# max32665 register map
Vendor: Maxim-Integrated; Series: ARMCM3; File version: 1.0
CPU: CM4 r2p1, little endian, MPU, FPU, 3 interrupt priority bits
Registers are 32-bit, read-write, reset 0x0 unless marked. A register's access mark holds for its fields unless they carry their own. Offsets are from the block's base; [hi:lo] are bit positions; {n}, {i} and the like mark numbered series.

## RPU — Resource Protection Unit
Base 0x40002000
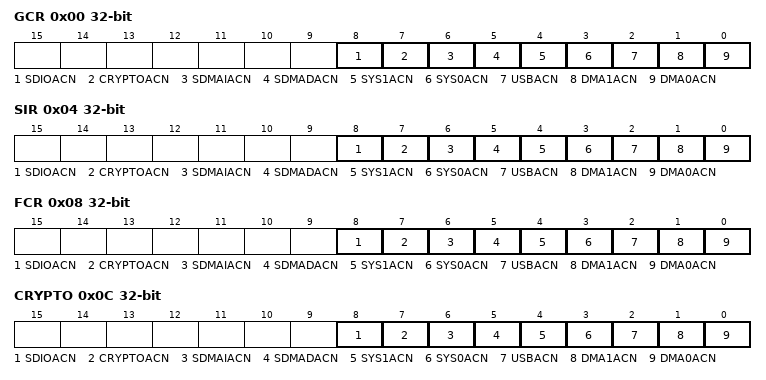
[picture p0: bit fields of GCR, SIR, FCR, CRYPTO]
0x00 GCR (reset mask 0xFFFFFE00) — GCR Protection Register
  [all] fields
    1=dis (Disallow); 0=allow
  [8] SDIOACN — Allow/Disallow SDIO access to the GCR
  [7] CRYPTOACN — Allow/Disallow CRYPTO access to the GCR
  [6] SDMAIACN — Allow/Disallow SDMA Instruction access to the GCR
  [5] SDMADACN — Allow/Disallow SDMA Data access to the GCR
  [4] SYS1ACN — Allow/Disallow SYS1 access to the GCR
  [3] SYS0ACN — Allow/Disallow SYS0 access to the GCR
  [2] USBACN — Allow/Disallow USB access to the GCR
  [1] DMA1ACN — Allow/Disallow DMA1 access to the GCR
  [0] DMA0ACN — Allow/Disallow DMA0 access to the GCR
0x04 SIR (reset mask 0xFFFFFE00) — SIR Protection Register
  [all] fields
    1=dis (Disallow); 0=allow
  [8] SDIOACN — Allow/Disallow SDIO access to the SIR
  [7] CRYPTOACN — Allow/Disallow CRYPTO access to the SIR
  [6] SDMAIACN — Allow/Disallow SDMA Instruction access to the SIR
  [5] SDMADACN — Allow/Disallow SDMA Data access to the SIR
  [4] SYS1ACN — Allow/Disallow SYS1 access to the SIR
  [3] SYS0ACN — Allow/Disallow SYS0 access to the SIR
  [2] USBACN — Allow/Disallow USB access to the SIR
  [1] DMA1ACN — Allow/Disallow DMA1 access to the SIR
  [0] DMA0ACN — Allow/Disallow DMA0 access to the SIR
0x08 FCR (reset mask 0xFFFFFE00) — FCR Protection Register
  [all] fields
    1=dis (Disallow); 0=allow
  [8] SDIOACN — Allow/Disallow SDIO access to the FCR
  [7] CRYPTOACN — Allow/Disallow CRYPTO access to the FCR
  [6] SDMAIACN — Allow/Disallow SDMA Instruction access to the FCR
  [5] SDMADACN — Allow/Disallow SDMA Data access to the FCR
  [4] SYS1ACN — Allow/Disallow SYS1 access to the FCR
  [3] SYS0ACN — Allow/Disallow SYS0 access to the FCR
  [2] USBACN — Allow/Disallow USB access to the FCR
  [1] DMA1ACN — Allow/Disallow DMA1 access to the FCR
  [0] DMA0ACN — Allow/Disallow DMA0 access to the FCR
0x0C CRYPTO (reset mask 0xFFFFFE00) — Crypto Protection Register
  [all] fields
    1=dis (Disallow); 0=allow
  [8] SDIOACN — Allow/Disallow SDIO access to the Crypto
  [7] CRYPTOACN — Allow/Disallow CRYPTO access to the Crypto
  [6] SDMAIACN — Allow/Disallow SDMA Instruction access to the Crypto
  [5] SDMADACN — Allow/Disallow SDMA Data access to the Crypto
  [4] SYS1ACN — Allow/Disallow SYS1 access to the Crypto
  [3] SYS0ACN — Allow/Disallow SYS0 access to the Crypto
  [2] USBACN — Allow/Disallow USB access to the Crypto
  [1] DMA1ACN — Allow/Disallow DMA1 access to the Crypto
  [0] DMA0ACN — Allow/Disallow DMA0 access to the Crypto
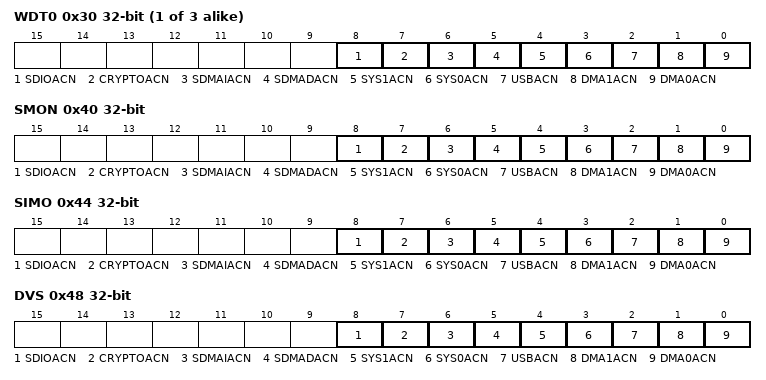
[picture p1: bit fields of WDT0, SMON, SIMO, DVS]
{0x30+4i} WDT{i} (reset mask 0xFFFFFE00) (i=0..2) — Watchdog {i} Protection Register
  [all] fields
    1=dis (Disallow); 0=allow
  [8] SDIOACN — Allow/Disallow SDIO access to the Watchdog {i}
  [7] CRYPTOACN — Allow/Disallow CRYPTO access to the Watchdog {i}
  [6] SDMAIACN — Allow/Disallow SDMA Instruction access to the Watchdog {i}
  [5] SDMADACN — Allow/Disallow SDMA Data access to the Watchdog {i}
  [4] SYS1ACN — Allow/Disallow SYS1 access to the Watchdog {i}
  [3] SYS0ACN — Allow/Disallow SYS0 access to the Watchdog {i}
  [2] USBACN — Allow/Disallow USB access to the Watchdog {i}
  [1] DMA1ACN — Allow/Disallow DMA1 access to the Watchdog {i}
  [0] DMA0ACN — Allow/Disallow DMA0 access to the Watchdog {i}
0x40 SMON (reset mask 0xFFFFFE00) — SMON Protection Register
  [all] fields
    1=dis (Disallow); 0=allow
  [8] SDIOACN — Allow/Disallow SDIO access to the SMON
  [7] CRYPTOACN — Allow/Disallow CRYPTO access to the SMON
  [6] SDMAIACN — Allow/Disallow SDMA Instruction access to the SMON
  [5] SDMADACN — Allow/Disallow SDMA Data access to the SMON
  [4] SYS1ACN — Allow/Disallow SYS1 access to the SMON
  [3] SYS0ACN — Allow/Disallow SYS0 access to the SMON
  [2] USBACN — Allow/Disallow USB access to the SMON
  [1] DMA1ACN — Allow/Disallow DMA1 access to the SMON
  [0] DMA0ACN — Allow/Disallow DMA0 access to the SMON
0x44 SIMO (reset mask 0xFFFFFE00) — SIMO Protection Register
  [all] fields
    1=dis (Disallow); 0=allow
  [8] SDIOACN — Allow/Disallow SDIO access to the SIMO
  [7] CRYPTOACN — Allow/Disallow CRYPTO access to the SIMO
  [6] SDMAIACN — Allow/Disallow SDMA Instruction access to the SIMO
  [5] SDMADACN — Allow/Disallow SDMA Data access to the SIMO
  [4] SYS1ACN — Allow/Disallow SYS1 access to the SIMO
  [3] SYS0ACN — Allow/Disallow SYS0 access to the SIMO
  [2] USBACN — Allow/Disallow USB access to the SIMO
  [1] DMA1ACN — Allow/Disallow DMA1 access to the SIMO
  [0] DMA0ACN — Allow/Disallow DMA0 access to the SIMO
0x48 DVS (reset mask 0xFFFFFE00) — DVS Protection Register
  [all] fields
    1=dis (Disallow); 0=allow
  [8] SDIOACN — Allow/Disallow SDIO access to the DVS
  [7] CRYPTOACN — Allow/Disallow CRYPTO access to the DVS
  [6] SDMAIACN — Allow/Disallow SDMA Instruction access to the DVS
  [5] SDMADACN — Allow/Disallow SDMA Data access to the DVS
  [4] SYS1ACN — Allow/Disallow SYS1 access to the DVS
  [3] SYS0ACN — Allow/Disallow SYS0 access to the DVS
  [2] USBACN — Allow/Disallow USB access to the DVS
  [1] DMA1ACN — Allow/Disallow DMA1 access to the DVS
  [0] DMA0ACN — Allow/Disallow DMA0 access to the DVS
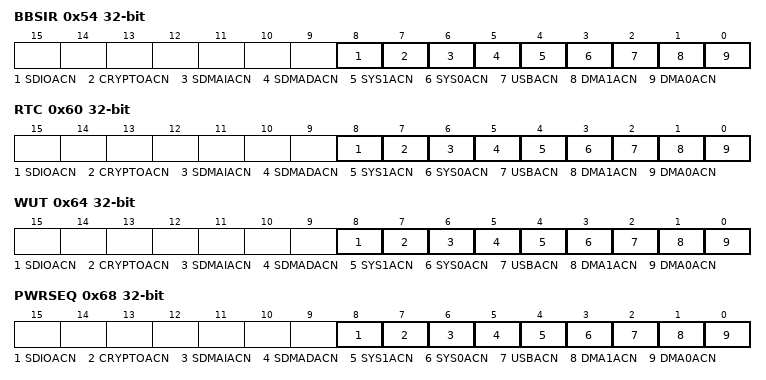
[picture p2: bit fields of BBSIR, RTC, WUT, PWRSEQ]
0x54 BBSIR (reset mask 0xFFFFFE00) — BBSIR Protection Register
  [all] fields
    1=dis (Disallow); 0=allow
  [8] SDIOACN — Allow/Disallow SDIO access to the BBSIR
  [7] CRYPTOACN — Allow/Disallow CRYPTO access to the BBSIR
  [6] SDMAIACN — Allow/Disallow SDMA Instruction access to the BBSIR
  [5] SDMADACN — Allow/Disallow SDMA Data access to the BBSIR
  [4] SYS1ACN — Allow/Disallow SYS1 access to the BBSIR
  [3] SYS0ACN — Allow/Disallow SYS0 access to the BBSIR
  [2] USBACN — Allow/Disallow USB access to the BBSIR
  [1] DMA1ACN — Allow/Disallow DMA1 access to the BBSIR
  [0] DMA0ACN — Allow/Disallow DMA0 access to the BBSIR
0x60 RTC (reset mask 0xFFFFFE00) — RTC Protection Register
  [all] fields
    1=dis (Disallow); 0=allow
  [8] SDIOACN — Allow/Disallow SDIO access to the RTC
  [7] CRYPTOACN — Allow/Disallow CRYPTO access to the RTC
  [6] SDMAIACN — Allow/Disallow SDMA Instruction access to the RTC
  [5] SDMADACN — Allow/Disallow SDMA Data access to the RTC
  [4] SYS1ACN — Allow/Disallow SYS1 access to the RTC
  [3] SYS0ACN — Allow/Disallow SYS0 access to the RTC
  [2] USBACN — Allow/Disallow USB access to the RTC
  [1] DMA1ACN — Allow/Disallow DMA1 access to the RTC
  [0] DMA0ACN — Allow/Disallow DMA0 access to the RTC
0x64 WUT (reset mask 0xFFFFFE00) — Wakeup Timer Protection Register
  [all] fields
    1=dis (Disallow); 0=allow
  [8] SDIOACN — Allow/Disallow SDIO access to the Wakeup Timer
  [7] CRYPTOACN — Allow/Disallow CRYPTO access to the Wakeup Timer
  [6] SDMAIACN — Allow/Disallow SDMA Instruction access to the Wakeup Timer
  [5] SDMADACN — Allow/Disallow SDMA Data access to the Wakeup Timer
  [4] SYS1ACN — Allow/Disallow SYS1 access to the Wakeup Timer
  [3] SYS0ACN — Allow/Disallow SYS0 access to the Wakeup Timer
  [2] USBACN — Allow/Disallow USB access to the Wakeup Timer
  [1] DMA1ACN — Allow/Disallow DMA1 access to the Wakeup Timer
  [0] DMA0ACN — Allow/Disallow DMA0 access to the Wakeup Timer
0x68 PWRSEQ (reset mask 0xFFFFFE00) — Power Sequencer Protection Register
  [all] fields
    1=dis (Disallow); 0=allow
  [8] SDIOACN — Allow/Disallow SDIO access to the Power Sequencer
  [7] CRYPTOACN — Allow/Disallow CRYPTO access to the Power Sequencer
  [6] SDMAIACN — Allow/Disallow SDMA Instruction access to the Power Sequencer
  [5] SDMADACN — Allow/Disallow SDMA Data access to the Power Sequencer
  [4] SYS1ACN — Allow/Disallow SYS1 access to the Power Sequencer
  [3] SYS0ACN — Allow/Disallow SYS0 access to the Power Sequencer
  [2] USBACN — Allow/Disallow USB access to the Power Sequencer
  [1] DMA1ACN — Allow/Disallow DMA1 access to the Power Sequencer
  [0] DMA0ACN — Allow/Disallow DMA0 access to the Power Sequencer
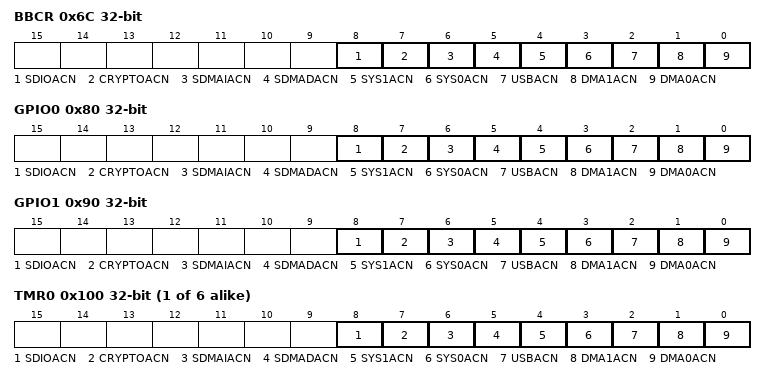
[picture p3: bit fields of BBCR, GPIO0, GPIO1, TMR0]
0x6C BBCR (reset mask 0xFFFFFE00) — BBCR Protection Register
  [all] fields
    1=dis (Disallow); 0=allow
  [8] SDIOACN — Allow/Disallow SDIO access to the BBCR
  [7] CRYPTOACN — Allow/Disallow CRYPTO access to the BBCR
  [6] SDMAIACN — Allow/Disallow SDMA Instruction access to the BBCR
  [5] SDMADACN — Allow/Disallow SDMA Data access to the BBCR
  [4] SYS1ACN — Allow/Disallow SYS1 access to the BBCR
  [3] SYS0ACN — Allow/Disallow SYS0 access to the BBCR
  [2] USBACN — Allow/Disallow USB access to the BBCR
  [1] DMA1ACN — Allow/Disallow DMA1 access to the BBCR
  [0] DMA0ACN — Allow/Disallow DMA0 access to the BBCR
0x80 GPIO0 (reset mask 0xFFFFFE00) — GPIO0 Protection Register
  [all] fields
    1=dis (Disallow); 0=allow
  [8] SDIOACN — Allow/Disallow SDIO access to the GPIO0
  [7] CRYPTOACN — Allow/Disallow CRYPTO access to the GPIO0
  [6] SDMAIACN — Allow/Disallow SDMA Instruction access to the GPIO0
  [5] SDMADACN — Allow/Disallow SDMA Data access to the GPIO0
  [4] SYS1ACN — Allow/Disallow SYS1 access to the GPIO0
  [3] SYS0ACN — Allow/Disallow SYS0 access to the GPIO0
  [2] USBACN — Allow/Disallow USB access to the GPIO0
  [1] DMA1ACN — Allow/Disallow DMA1 access to the GPIO0
  [0] DMA0ACN — Allow/Disallow DMA0 access to the GPIO0
0x90 GPIO1 (reset mask 0xFFFFFE00) — GPIO1 Protection Register
  [all] fields
    1=dis (Disallow); 0=allow
  [8] SDIOACN — Allow/Disallow SDIO access to the GPIO1
  [7] CRYPTOACN — Allow/Disallow CRYPTO access to the GPIO1
  [6] SDMAIACN — Allow/Disallow SDMA Instruction access to the GPIO1
  [5] SDMADACN — Allow/Disallow SDMA Data access to the GPIO1
  [4] SYS1ACN — Allow/Disallow SYS1 access to the GPIO1
  [3] SYS0ACN — Allow/Disallow SYS0 access to the GPIO1
  [2] USBACN — Allow/Disallow USB access to the GPIO1
  [1] DMA1ACN — Allow/Disallow DMA1 access to the GPIO1
  [0] DMA0ACN — Allow/Disallow DMA0 access to the GPIO1
{0x100+0x10*i} TMR{i} (reset mask 0xFFFFFE00) (i=0..5) — TMR{i} Protection Register
  [all] fields
    1=dis (Disallow); 0=allow
  [8] SDIOACN — Allow/Disallow SDIO access to the TMR{i}
  [7] CRYPTOACN — Allow/Disallow CRYPTO access to the TMR{i}
  [6] SDMAIACN — Allow/Disallow SDMA Instruction access to the TMR{i}
  [5] SDMADACN — Allow/Disallow SDMA Data access to the TMR{i}
  [4] SYS1ACN — Allow/Disallow SYS1 access to the TMR{i}
  [3] SYS0ACN — Allow/Disallow SYS0 access to the TMR{i}
  [2] USBACN — Allow/Disallow USB access to the TMR{i}
  [1] DMA1ACN — Allow/Disallow DMA1 access to the TMR{i}
  [0] DMA0ACN — Allow/Disallow DMA0 access to the TMR{i}
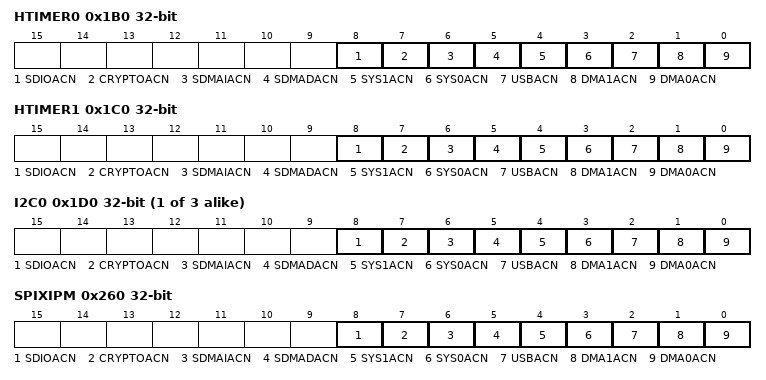
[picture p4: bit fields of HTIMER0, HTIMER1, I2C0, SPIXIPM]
0x1B0 HTIMER0 (reset mask 0xFFFFFE00) — HTimer0 Protection Register
  [all] fields
    1=dis (Disallow); 0=allow
  [8] SDIOACN — Allow/Disallow SDIO access to the HTimer0
  [7] CRYPTOACN — Allow/Disallow CRYPTO access to the HTimer0
  [6] SDMAIACN — Allow/Disallow SDMA Instruction access to the HTimer0
  [5] SDMADACN — Allow/Disallow SDMA Data access to the HTimer0
  [4] SYS1ACN — Allow/Disallow SYS1 access to the HTimer0
  [3] SYS0ACN — Allow/Disallow SYS0 access to the HTimer0
  [2] USBACN — Allow/Disallow USB access to the HTimer0
  [1] DMA1ACN — Allow/Disallow DMA1 access to the HTimer0
  [0] DMA0ACN — Allow/Disallow DMA0 access to the HTimer0
0x1C0 HTIMER1 (reset mask 0xFFFFFE00) — HTimer1 Protection Register
  [all] fields
    1=dis (Disallow); 0=allow
  [8] SDIOACN — Allow/Disallow SDIO access to the HTimer1
  [7] CRYPTOACN — Allow/Disallow CRYPTO access to the HTimer1
  [6] SDMAIACN — Allow/Disallow SDMA Instruction access to the HTimer1
  [5] SDMADACN — Allow/Disallow SDMA Data access to the HTimer1
  [4] SYS1ACN — Allow/Disallow SYS1 access to the HTimer1
  [3] SYS0ACN — Allow/Disallow SYS0 access to the HTimer1
  [2] USBACN — Allow/Disallow USB access to the HTimer1
  [1] DMA1ACN — Allow/Disallow DMA1 access to the HTimer1
  [0] DMA0ACN — Allow/Disallow DMA0 access to the HTimer1
{0x1D0+0x10*i} I2C{i} (reset mask 0xFFFFFE00) (i=0..2) — I2C{i} Protection Register
  [all] fields
    1=dis (Disallow); 0=allow
  [8] SDIOACN — Allow/Disallow SDIO access to the I2C{i}
  [7] CRYPTOACN — Allow/Disallow CRYPTO access to the I2C{i}
  [6] SDMAIACN — Allow/Disallow SDMA Instruction access to the I2C{i}
  [5] SDMADACN — Allow/Disallow SDMA Data access to the I2C{i}
  [4] SYS1ACN — Allow/Disallow SYS1 access to the I2C{i}
  [3] SYS0ACN — Allow/Disallow SYS0 access to the I2C{i}
  [2] USBACN — Allow/Disallow USB access to the I2C{i}
  [1] DMA1ACN — Allow/Disallow DMA1 access to the I2C{i}
  [0] DMA0ACN — Allow/Disallow DMA0 access to the I2C{i}
0x260 SPIXIPM (reset mask 0xFFFFFE00) — SPI-XIP Master Protection Register
  [all] fields
    1=dis (Disallow); 0=allow
  [8] SDIOACN — Allow/Disallow SDIO access to the SPI-XIP Master
  [7] CRYPTOACN — Allow/Disallow CRYPTO access to the SPI-XIP Master
  [6] SDMAIACN — Allow/Disallow SDMA Instruction access to the SPI-XIP Master
  [5] SDMADACN — Allow/Disallow SDMA Data access to the SPI-XIP Master
  [4] SYS1ACN — Allow/Disallow SYS1 access to the SPI-XIP Master
  [3] SYS0ACN — Allow/Disallow SYS0 access to the SPI-XIP Master
  [2] USBACN — Allow/Disallow USB access to the SPI-XIP Master
  [1] DMA1ACN — Allow/Disallow DMA1 access to the SPI-XIP Master
  [0] DMA0ACN — Allow/Disallow DMA0 access to the SPI-XIP Master
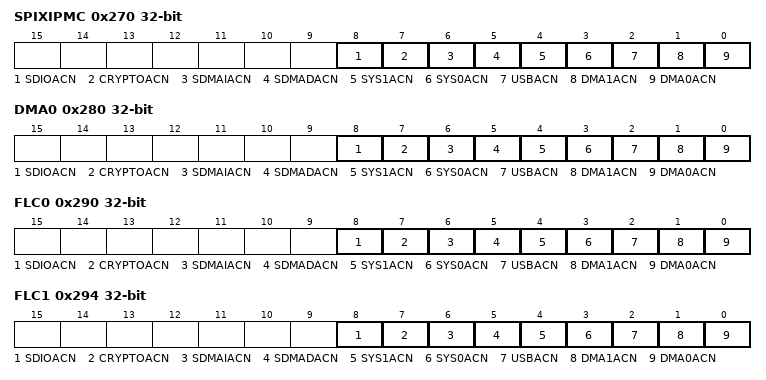
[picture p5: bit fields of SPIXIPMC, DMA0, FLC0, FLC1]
0x270 SPIXIPMC (reset mask 0xFFFFFE00) — SPI-XIP Master Controller Protection Register
  [all] fields
    1=dis (Disallow); 0=allow
  [8] SDIOACN — Allow/Disallow SDIO access to the SPI-XIP Master Controller
  [7] CRYPTOACN — Allow/Disallow CRYPTO access to the SPI-XIP Master Controller
  [6] SDMAIACN — Allow/Disallow SDMA Instruction access to the SPI-XIP Master Controller
  [5] SDMADACN — Allow/Disallow SDMA Data access to the SPI-XIP Master Controller
  [4] SYS1ACN — Allow/Disallow SYS1 access to the SPI-XIP Master Controller
  [3] SYS0ACN — Allow/Disallow SYS0 access to the SPI-XIP Master Controller
  [2] USBACN — Allow/Disallow USB access to the SPI-XIP Master Controller
  [1] DMA1ACN — Allow/Disallow DMA1 access to the SPI-XIP Master Controller
  [0] DMA0ACN — Allow/Disallow DMA0 access to the SPI-XIP Master Controller
0x280 DMA0 (reset mask 0xFFFFFE00) — DMA0 Protection Register
  [all] fields
    1=dis (Disallow); 0=allow
  [8] SDIOACN — Allow/Disallow SDIO access to the DMA0
  [7] CRYPTOACN — Allow/Disallow CRYPTO access to the DMA0
  [6] SDMAIACN — Allow/Disallow SDMA Instruction access to the DMA0
  [5] SDMADACN — Allow/Disallow SDMA Data access to the DMA0
  [4] SYS1ACN — Allow/Disallow SYS1 access to the DMA0
  [3] SYS0ACN — Allow/Disallow SYS0 access to the DMA0
  [2] USBACN — Allow/Disallow USB access to the DMA0
  [1] DMA1ACN — Allow/Disallow DMA1 access to the DMA0
  [0] DMA0ACN — Allow/Disallow DMA0 access to the DMA0
0x290 FLC0 (reset mask 0xFFFFFE00) — Flash 0 Protection Register
  [all] fields
    1=dis (Disallow); 0=allow
  [8] SDIOACN — Allow/Disallow SDIO access to the Flash 0
  [7] CRYPTOACN — Allow/Disallow CRYPTO access to the Flash 0
  [6] SDMAIACN — Allow/Disallow SDMA Instruction access to the Flash 0
  [5] SDMADACN — Allow/Disallow SDMA Data access to the Flash 0
  [4] SYS1ACN — Allow/Disallow SYS1 access to the Flash 0
  [3] SYS0ACN — Allow/Disallow SYS0 access to the Flash 0
  [2] USBACN — Allow/Disallow USB access to the Flash 0
  [1] DMA1ACN — Allow/Disallow DMA1 access to the Flash 0
  [0] DMA0ACN — Allow/Disallow DMA0 access to the Flash 0
0x294 FLC1 (reset mask 0xFFFFFE00) — Flash 1 Protection Register
  [all] fields
    1=dis (Disallow); 0=allow
  [8] SDIOACN — Allow/Disallow SDIO access to the Flash 1
  [7] CRYPTOACN — Allow/Disallow CRYPTO access to the Flash 1
  [6] SDMAIACN — Allow/Disallow SDMA Instruction access to the Flash 1
  [5] SDMADACN — Allow/Disallow SDMA Data access to the Flash 1
  [4] SYS1ACN — Allow/Disallow SYS1 access to the Flash 1
  [3] SYS0ACN — Allow/Disallow SYS0 access to the Flash 1
  [2] USBACN — Allow/Disallow USB access to the Flash 1
  [1] DMA1ACN — Allow/Disallow DMA1 access to the Flash 1
  [0] DMA0ACN — Allow/Disallow DMA0 access to the Flash 1
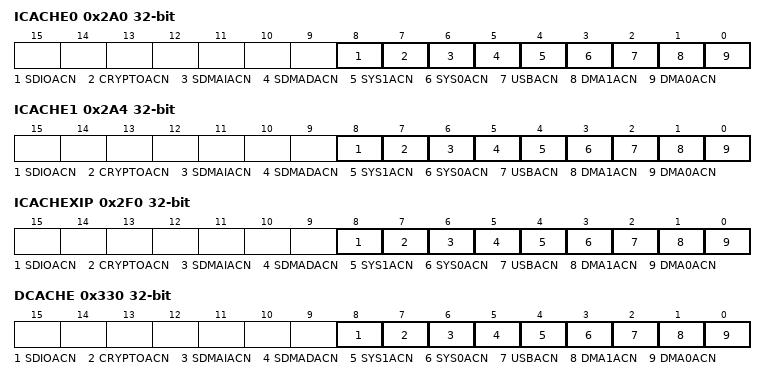
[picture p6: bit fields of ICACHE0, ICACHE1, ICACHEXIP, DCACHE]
0x2A0 ICACHE0 (reset mask 0xFFFFFE00) — Instruction Cache 0 Protection Register
  [all] fields
    1=dis (Disallow); 0=allow
  [8] SDIOACN — Allow/Disallow SDIO access to the Instruction Cache 0
  [7] CRYPTOACN — Allow/Disallow CRYPTO access to the Instruction Cache 0
  [6] SDMAIACN — Allow/Disallow SDMA Instruction access to the Instruction Cache 0
  [5] SDMADACN — Allow/Disallow SDMA Data access to the Instruction Cache 0
  [4] SYS1ACN — Allow/Disallow SYS1 access to the Instruction Cache 0
  [3] SYS0ACN — Allow/Disallow SYS0 access to the Instruction Cache 0
  [2] USBACN — Allow/Disallow USB access to the Instruction Cache 0
  [1] DMA1ACN — Allow/Disallow DMA1 access to the Instruction Cache 0
  [0] DMA0ACN — Allow/Disallow DMA0 access to the Instruction Cache 0
0x2A4 ICACHE1 (reset mask 0xFFFFFE00) — Instruction Cache 1 Protection Register
  [all] fields
    1=dis (Disallow); 0=allow
  [8] SDIOACN — Allow/Disallow SDIO access to the Instruction Cache 1
  [7] CRYPTOACN — Allow/Disallow CRYPTO access to the Instruction Cache 1
  [6] SDMAIACN — Allow/Disallow SDMA Instruction access to the Instruction Cache 1
  [5] SDMADACN — Allow/Disallow SDMA Data access to the Instruction Cache 1
  [4] SYS1ACN — Allow/Disallow SYS1 access to the Instruction Cache 1
  [3] SYS0ACN — Allow/Disallow SYS0 access to the Instruction Cache 1
  [2] USBACN — Allow/Disallow USB access to the Instruction Cache 1
  [1] DMA1ACN — Allow/Disallow DMA1 access to the Instruction Cache 1
  [0] DMA0ACN — Allow/Disallow DMA0 access to the Instruction Cache 1
0x2F0 ICACHEXIP (reset mask 0xFFFFFE00) — Instruction Cache XIP Protection Register
  [all] fields
    1=dis (Disallow); 0=allow
  [8] SDIOACN — Allow/Disallow SDIO access to the Instruction Cache XIP
  [7] CRYPTOACN — Allow/Disallow CRYPTO access to the Instruction Cache XIP
  [6] SDMAIACN — Allow/Disallow SDMA Instruction access to the Instruction Cache XIP
  [5] SDMADACN — Allow/Disallow SDMA Data access to the Instruction Cache XIP
  [4] SYS1ACN — Allow/Disallow SYS1 access to the Instruction Cache XIP
  [3] SYS0ACN — Allow/Disallow SYS0 access to the Instruction Cache XIP
  [2] USBACN — Allow/Disallow USB access to the Instruction Cache XIP
  [1] DMA1ACN — Allow/Disallow DMA1 access to the Instruction Cache XIP
  [0] DMA0ACN — Allow/Disallow DMA0 access to the Instruction Cache XIP
0x330 DCACHE (reset mask 0xFFFFFE00) — Data Cache Controller Protection Register
  [all] fields
    1=dis (Disallow); 0=allow
  [8] SDIOACN — Allow/Disallow SDIO access to the Data Cache Controller
  [7] CRYPTOACN — Allow/Disallow CRYPTO access to the Data Cache Controller
  [6] SDMAIACN — Allow/Disallow SDMA Instruction access to the Data Cache Controller
  [5] SDMADACN — Allow/Disallow SDMA Data access to the Data Cache Controller
  [4] SYS1ACN — Allow/Disallow SYS1 access to the Data Cache Controller
  [3] SYS0ACN — Allow/Disallow SYS0 access to the Data Cache Controller
  [2] USBACN — Allow/Disallow USB access to the Data Cache Controller
  [1] DMA1ACN — Allow/Disallow DMA1 access to the Data Cache Controller
  [0] DMA0ACN — Allow/Disallow DMA0 access to the Data Cache Controller
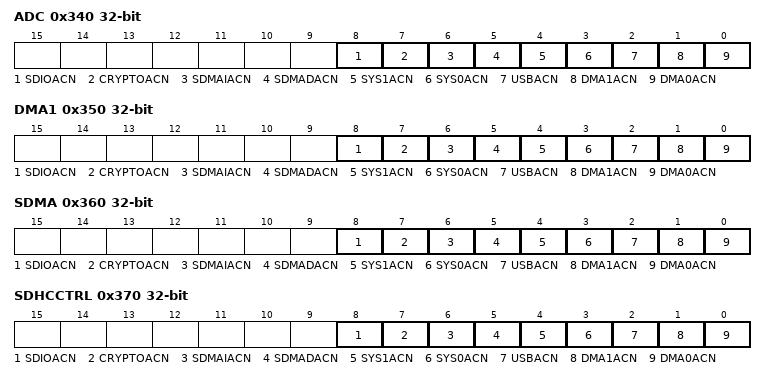
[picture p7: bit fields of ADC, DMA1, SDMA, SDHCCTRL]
0x340 ADC (reset mask 0xFFFFFE00) — ADC Protection Register
  [all] fields
    1=dis (Disallow); 0=allow
  [8] SDIOACN — Allow/Disallow SDIO access to the ADC
  [7] CRYPTOACN — Allow/Disallow CRYPTO access to the ADC
  [6] SDMAIACN — Allow/Disallow SDMA Instruction access to the ADC
  [5] SDMADACN — Allow/Disallow SDMA Data access to the ADC
  [4] SYS1ACN — Allow/Disallow SYS1 access to the ADC
  [3] SYS0ACN — Allow/Disallow SYS0 access to the ADC
  [2] USBACN — Allow/Disallow USB access to the ADC
  [1] DMA1ACN — Allow/Disallow DMA1 access to the ADC
  [0] DMA0ACN — Allow/Disallow DMA0 access to the ADC
0x350 DMA1 (reset mask 0xFFFFFE00) — DMA1 Protection Register
  [all] fields
    1=dis (Disallow); 0=allow
  [8] SDIOACN — Allow/Disallow SDIO access to the DMA1
  [7] CRYPTOACN — Allow/Disallow CRYPTO access to the DMA1
  [6] SDMAIACN — Allow/Disallow SDMA Instruction access to the DMA1
  [5] SDMADACN — Allow/Disallow SDMA Data access to the DMA1
  [4] SYS1ACN — Allow/Disallow SYS1 access to the DMA1
  [3] SYS0ACN — Allow/Disallow SYS0 access to the DMA1
  [2] USBACN — Allow/Disallow USB access to the DMA1
  [1] DMA1ACN — Allow/Disallow DMA1 access to the DMA1
  [0] DMA0ACN — Allow/Disallow DMA0 access to the DMA1
0x360 SDMA (reset mask 0xFFFFFE00) — SDMA Protection Register
  [all] fields
    1=dis (Disallow); 0=allow
  [8] SDIOACN — Allow/Disallow SDIO access to the SDMA
  [7] CRYPTOACN — Allow/Disallow CRYPTO access to the SDMA
  [6] SDMAIACN — Allow/Disallow SDMA Instruction access to the SDMA
  [5] SDMADACN — Allow/Disallow SDMA Data access to the SDMA
  [4] SYS1ACN — Allow/Disallow SYS1 access to the SDMA
  [3] SYS0ACN — Allow/Disallow SYS0 access to the SDMA
  [2] USBACN — Allow/Disallow USB access to the SDMA
  [1] DMA1ACN — Allow/Disallow DMA1 access to the SDMA
  [0] DMA0ACN — Allow/Disallow DMA0 access to the SDMA
0x370 SDHCCTRL (reset mask 0xFFFFFE00) — SDHC Controller Protection Register
  [all] fields
    1=dis (Disallow); 0=allow
  [8] SDIOACN — Allow/Disallow SDIO access to the SDHC Controller
  [7] CRYPTOACN — Allow/Disallow CRYPTO access to the SDHC Controller
  [6] SDMAIACN — Allow/Disallow SDMA Instruction access to the SDHC Controller
  [5] SDMADACN — Allow/Disallow SDMA Data access to the SDHC Controller
  [4] SYS1ACN — Allow/Disallow SYS1 access to the SDHC Controller
  [3] SYS0ACN — Allow/Disallow SYS0 access to the SDHC Controller
  [2] USBACN — Allow/Disallow USB access to the SDHC Controller
  [1] DMA1ACN — Allow/Disallow DMA1 access to the SDHC Controller
  [0] DMA0ACN — Allow/Disallow DMA0 access to the SDHC Controller
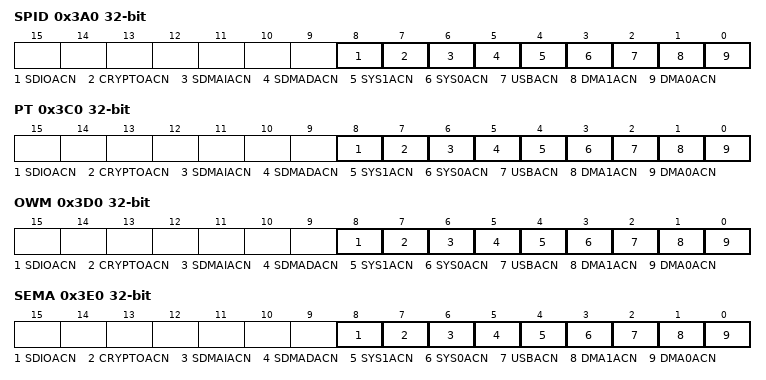
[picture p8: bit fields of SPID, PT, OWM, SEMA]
0x3A0 SPID (reset mask 0xFFFFFE00) — SPI Data Controller Protection Register
  [all] fields
    1=dis (Disallow); 0=allow
  [8] SDIOACN — Allow/Disallow SDIO access to the SPID
  [7] CRYPTOACN — Allow/Disallow CRYPTO access to the SPI Data Controller
  [6] SDMAIACN — Allow/Disallow SDMA Instruction access to the SPI Data Controller
  [5] SDMADACN — Allow/Disallow SDMA Data access to the SPI Data Controller
  [4] SYS1ACN — Allow/Disallow SYS1 access to the SPI Data Controller
  [3] SYS0ACN — Allow/Disallow SYS0 access to the SPI Data Controller
  [2] USBACN — Allow/Disallow USB access to the SPI Data Controller
  [1] DMA1ACN — Allow/Disallow DMA1 access to the SPI Data Controller
  [0] DMA0ACN — Allow/Disallow DMA0 access to the SPI Data Controller
0x3C0 PT (reset mask 0xFFFFFE00) — Pulse Train Protection Register
  [all] fields
    1=dis (Disallow); 0=allow
  [8] SDIOACN — Allow/Disallow SDIO access to the Pulse Train
  [7] CRYPTOACN — Allow/Disallow CRYPTO access to the Pulse Train
  [6] SDMAIACN — Allow/Disallow SDMA Instruction access to the Pulse Train
  [5] SDMADACN — Allow/Disallow SDMA Data access to the Pulse Train
  [4] SYS1ACN — Allow/Disallow SYS1 access to the Pulse Train
  [3] SYS0ACN — Allow/Disallow SYS0 access to the Pulse Train
  [2] USBACN — Allow/Disallow USB access to the Pulse Train
  [1] DMA1ACN — Allow/Disallow DMA1 access to the Pulse Train
  [0] DMA0ACN — Allow/Disallow DMA0 access to the Pulse Train
0x3D0 OWM (reset mask 0xFFFFFE00) — One Wire Master Protection Register
  [all] fields
    1=dis (Disallow); 0=allow
  [8] SDIOACN — Allow/Disallow SDIO access to the One Wire Master
  [7] CRYPTOACN — Allow/Disallow CRYPTO access to the One Wire Master
  [6] SDMAIACN — Allow/Disallow SDMA Instruction access to the One Wire Master
  [5] SDMADACN — Allow/Disallow SDMA Data access to the One Wire Master
  [4] SYS1ACN — Allow/Disallow SYS1 access to the One Wire Master
  [3] SYS0ACN — Allow/Disallow SYS0 access to the One Wire Master
  [2] USBACN — Allow/Disallow USB access to the One Wire Master
  [1] DMA1ACN — Allow/Disallow DMA1 access to the One Wire Master
  [0] DMA0ACN — Allow/Disallow DMA0 access to the One Wire Master
0x3E0 SEMA (reset mask 0xFFFFFE00) — Semaphores Protection Register
  [all] fields
    1=dis (Disallow); 0=allow
  [8] SDIOACN — Allow/Disallow SDIO access to the Semaphores
  [7] CRYPTOACN — Allow/Disallow CRYPTO access to the Semaphores
  [6] SDMAIACN — Allow/Disallow SDMA Instruction access to the Semaphores
  [5] SDMADACN — Allow/Disallow SDMA Data access to the Semaphores
  [4] SYS1ACN — Allow/Disallow SYS1 access to the Semaphores
  [3] SYS0ACN — Allow/Disallow SYS0 access to the Semaphores
  [2] USBACN — Allow/Disallow USB access to the Semaphores
  [1] DMA1ACN — Allow/Disallow DMA1 access to the Semaphores
  [0] DMA0ACN — Allow/Disallow DMA0 access to the Semaphores
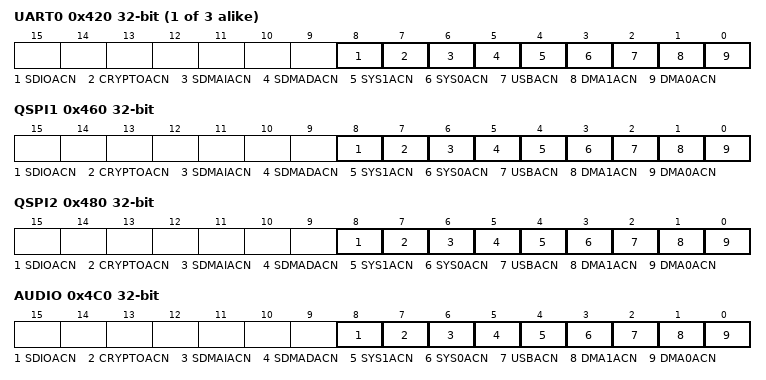
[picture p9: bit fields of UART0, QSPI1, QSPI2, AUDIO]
{0x420+0x10*i} UART{i} (reset mask 0xFFFFFE00) (i=0..2) — UART{i} Protection Register
  [all] fields
    1=dis (Disallow); 0=allow
  [8] SDIOACN — Allow/Disallow SDIO access to the UART{i}
  [7] CRYPTOACN — Allow/Disallow CRYPTO access to the UART{i}
  [6] SDMAIACN — Allow/Disallow SDMA Instruction access to the UART{i}
  [5] SDMADACN — Allow/Disallow SDMA Data access to the UART{i}
  [4] SYS1ACN — Allow/Disallow SYS1 access to the UART{i}
  [3] SYS0ACN — Allow/Disallow SYS0 access to the UART{i}
  [2] USBACN — Allow/Disallow USB access to the UART{i}
  [1] DMA1ACN — Allow/Disallow DMA1 access to the UART{i}
  [0] DMA0ACN — Allow/Disallow DMA0 access to the UART{i}
0x460 QSPI1 (reset mask 0xFFFFFE00) — QSPI1 Protection Register
  [all] fields
    1=dis (Disallow); 0=allow
  [8] SDIOACN — Allow/Disallow SDIO access to the QSPI1
  [7] CRYPTOACN — Allow/Disallow CRYPTO access to the QSPI1
  [6] SDMAIACN — Allow/Disallow SDMA Instruction access to the QSPI1
  [5] SDMADACN — Allow/Disallow SDMA Data access to the QSPI1
  [4] SYS1ACN — Allow/Disallow SYS1 access to the QSPI1
  [3] SYS0ACN — Allow/Disallow SYS0 access to the QSPI1
  [2] USBACN — Allow/Disallow USB access to the QSPI1
  [1] DMA1ACN — Allow/Disallow DMA1 access to the QSPI1
  [0] DMA0ACN — Allow/Disallow DMA0 access to the QSPI1
0x480 QSPI2 (reset mask 0xFFFFFE00) — QSPI2 Protection Register
  [all] fields
    1=dis (Disallow); 0=allow
  [8] SDIOACN — Allow/Disallow SDIO access to the QSPI2
  [7] CRYPTOACN — Allow/Disallow CRYPTO access to the QSPI2
  [6] SDMAIACN — Allow/Disallow SDMA Instruction access to the QSPI2
  [5] SDMADACN — Allow/Disallow SDMA Data access to the QSPI2
  [4] SYS1ACN — Allow/Disallow SYS1 access to the QSPI2
  [3] SYS0ACN — Allow/Disallow SYS0 access to the QSPI2
  [2] USBACN — Allow/Disallow USB access to the QSPI2
  [1] DMA1ACN — Allow/Disallow DMA1 access to the QSPI2
  [0] DMA0ACN — Allow/Disallow DMA0 access to the QSPI2
0x4C0 AUDIO (reset mask 0xFFFFFE00) — Audio Subsystem Protection Register
  [all] fields
    1=dis (Disallow); 0=allow
  [8] SDIOACN — Allow/Disallow SDIO access to the Audio Subsystem
  [7] CRYPTOACN — Allow/Disallow CRYPTO access to the Audio Subsystem
  [6] SDMAIACN — Allow/Disallow SDMA Instruction access to the Audio Subsystem
  [5] SDMADACN — Allow/Disallow SDMA Data access to the Audio Subsystem
  [4] SYS1ACN — Allow/Disallow SYS1 access to the Audio Subsystem
  [3] SYS0ACN — Allow/Disallow SYS0 access to the Audio Subsystem
  [2] USBACN — Allow/Disallow USB access to the Audio Subsystem
  [1] DMA1ACN — Allow/Disallow DMA1 access to the Audio Subsystem
  [0] DMA0ACN — Allow/Disallow DMA0 access to the Audio Subsystem
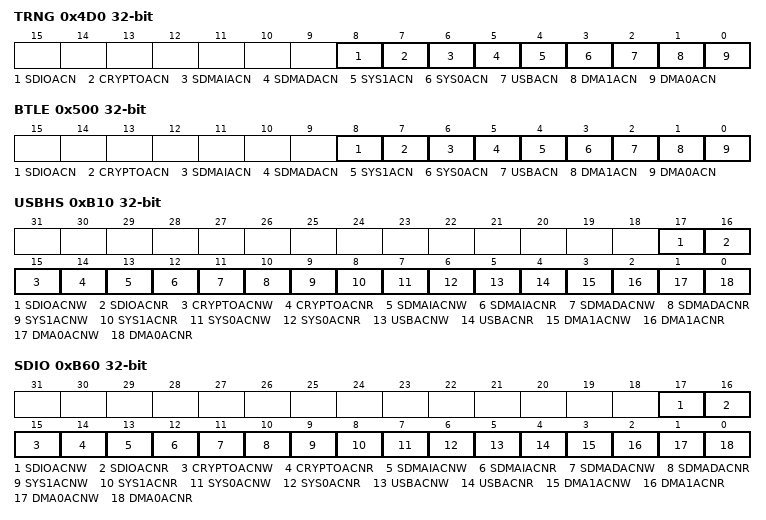
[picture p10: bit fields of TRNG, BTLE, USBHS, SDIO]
0x4D0 TRNG (reset mask 0xFFFFFE00) — TRNG Protection Register
  [all] fields
    1=dis (Disallow); 0=allow
  [8] SDIOACN — Allow/Disallow SDIO access to the TRNG
  [7] CRYPTOACN — Allow/Disallow CRYPTO access to the TRNG
  [6] SDMAIACN — Allow/Disallow SDMA Instruction access to the TRNG
  [5] SDMADACN — Allow/Disallow SDMA Data access to the TRNG
  [4] SYS1ACN — Allow/Disallow SYS1 access to the TRNG
  [3] SYS0ACN — Allow/Disallow SYS0 access to the TRNG
  [2] USBACN — Allow/Disallow USB access to the TRNG
  [1] DMA1ACN — Allow/Disallow DMA1 access to the TRNG
  [0] DMA0ACN — Allow/Disallow DMA0 access to the TRNG
0x500 BTLE (reset mask 0xFFFFFE00) — BTLE Registers Protection Register
  [all] fields
    1=dis (Disallow); 0=allow
  [8] SDIOACN — Allow/Disallow SDIO access to the BTLE Registers
  [7] CRYPTOACN — Allow/Disallow CRYPTO access to the BTLE Registers
  [6] SDMAIACN — Allow/Disallow SDMA Instruction access to the BTLE Registers
  [5] SDMADACN — Allow/Disallow SDMA Data access to the BTLE Registers
  [4] SYS1ACN — Allow/Disallow SYS1 access to the BTLE Registers
  [3] SYS0ACN — Allow/Disallow SYS0 access to the BTLE Registers
  [2] USBACN — Allow/Disallow USB access to the BTLE Registers
  [1] DMA1ACN — Allow/Disallow DMA1 access to the BTLE Registers
  [0] DMA0ACN — Allow/Disallow DMA0 access to the BTLE Registers
0xB10 USBHS (reset mask 0xFFFFFE00) — USBHS Protection Register
  [all] fields
    1=dis (Disallow); 0=allow
  [17] SDIOACNW — Allow/Disallow SDIO Write access to the USBHS
  [16] SDIOACNR — Allow/Disallow SDIO Read access to the USBHS
  [15] CRYPTOACNW — Allow/Disallow CRYPTO Write access to the USBHS
  [14] CRYPTOACNR — Allow/Disallow CRYPTO Read access to the USBHS
  [13] SDMAIACNW — Allow/Disallow SDMA Instruction Write access to the USBHS
  [12] SDMAIACNR — Allow/Disallow SDMA Instruction Read access to the USBHS
  [11] SDMADACNW — Allow/Disallow SDMA Data Write access to the USBHS
  [10] SDMADACNR — Allow/Disallow SDMA Data Read access to the USBHS
  [9] SYS1ACNW — Allow/Disallow SYS1 Write access to the USBHS
  [8] SYS1ACNR — Allow/Disallow SYS1 Read access to the USBHS
  [7] SYS0ACNW — Allow/Disallow SYS0 Write access to the USBHS
  [6] SYS0ACNR — Allow/Disallow SYS0 Read access to the USBHS
  [5] USBACNW — Allow/Disallow USB Write access to the USBHS
  [4] USBACNR — Allow/Disallow USB Read access to the USBHS
  [3] DMA1ACNW — Allow/Disallow DMA1 Write access to the USBHS
  [2] DMA1ACNR — Allow/Disallow DMA1 Read access to the USBHS
  [1] DMA0ACNW — Allow/Disallow DMA0 Write access to the USBHS
  [0] DMA0ACNR — Allow/Disallow DMA0 Read access to the USBHS
0xB60 SDIO (reset mask 0xFFFFFE00) — SDIO Protection Register
  [all] fields
    1=dis (Disallow); 0=allow
  [17] SDIOACNW — Allow/Disallow SDIO Write access to the SDIO
  [16] SDIOACNR — Allow/Disallow SDIO Read access to the SDIO
  [15] CRYPTOACNW — Allow/Disallow CRYPTO Write access to the SDIO
  [14] CRYPTOACNR — Allow/Disallow CRYPTO Read access to the SDIO
  [13] SDMAIACNW — Allow/Disallow SDMA Instruction Write access to the SDIO
  [12] SDMAIACNR — Allow/Disallow SDMA Instruction Read access to the SDIO
  [11] SDMADACNW — Allow/Disallow SDMA Data Write access to the SDIO
  [10] SDMADACNR — Allow/Disallow SDMA Data Read access to the SDIO
  [9] SYS1ACNW — Allow/Disallow SYS1 Write access to the SDIO
  [8] SYS1ACNR — Allow/Disallow SYS1 Read access to the SDIO
  [7] SYS0ACNW — Allow/Disallow SYS0 Write access to the SDIO
  [6] SYS0ACNR — Allow/Disallow SYS0 Read access to the SDIO
  [5] USBACNW — Allow/Disallow USB Write access to the SDIO
  [4] USBACNR — Allow/Disallow USB Read access to the SDIO
  [3] DMA1ACNW — Allow/Disallow DMA1 Write access to the SDIO
  [2] DMA1ACNR — Allow/Disallow DMA1 Read access to the SDIO
  [1] DMA0ACNW — Allow/Disallow DMA0 Write access to the SDIO
  [0] DMA0ACNR — Allow/Disallow DMA0 Read access to the SDIO
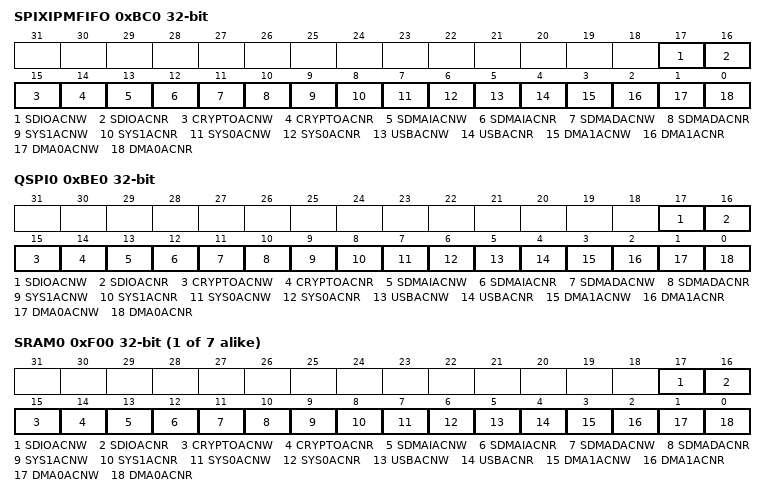
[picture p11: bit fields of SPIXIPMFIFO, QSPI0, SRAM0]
0xBC0 SPIXIPMFIFO (reset mask 0xFFFFFE00) — SPI XIP Master FIFO Protection Register
  [all] fields
    1=dis (Disallow); 0=allow
  [17] SDIOACNW — Allow/Disallow SDIO Write access to the SPI XIP Master FIFO
  [16] SDIOACNR — Allow/Disallow SDIO Read access to the SPI XIP Master FIFO
  [15] CRYPTOACNW — Allow/Disallow CRYPTO Write access to the SPI XIP Master FIFO
  [14] CRYPTOACNR — Allow/Disallow CRYPTO Read access to the SPI XIP Master FIFO
  [13] SDMAIACNW — Allow/Disallow SDMA Instruction Write access to the SPI XIP Master FIFO
  [12] SDMAIACNR — Allow/Disallow SDMA Instruction Read access to the SPI XIP Master FIFO
  [11] SDMADACNW — Allow/Disallow SDMA Data Write access to the SPI XIP Master FIFO
  [10] SDMADACNR — Allow/Disallow SDMA Data Read access to the SPI XIP Master FIFO
  [9] SYS1ACNW — Allow/Disallow SYS1 Write access to the SPI XIP Master FIFO
  [8] SYS1ACNR — Allow/Disallow SYS1 Read access to the SPI XIP Master FIFO
  [7] SYS0ACNW — Allow/Disallow SYS0 Write access to the SPI XIP Master FIFO
  [6] SYS0ACNR — Allow/Disallow SYS0 Read access to the SPI XIP Master FIFO
  [5] USBACNW — Allow/Disallow USB Write access to the SPI XIP Master FIFO
  [4] USBACNR — Allow/Disallow USB Read access to the SPI XIP Master FIFO
  [3] DMA1ACNW — Allow/Disallow DMA1 Write access to the SPI XIP Master FIFO
  [2] DMA1ACNR — Allow/Disallow DMA1 Read access to the SPI XIP Master FIFO
  [1] DMA0ACNW — Allow/Disallow DMA0 Write access to the SPI XIP Master FIFO
  [0] DMA0ACNR — Allow/Disallow DMA0 Read access to the SPI XIP Master FIFO
0xBE0 QSPI0 (reset mask 0xFFFFFE00) — QSPI0 Protection Register
  [all] fields
    1=dis (Disallow); 0=allow
  [17] SDIOACNW — Allow/Disallow SDIO Write access to the QSPI0
  [16] SDIOACNR — Allow/Disallow SDIO Read access to the QSPI0
  [15] CRYPTOACNW — Allow/Disallow CRYPTO Write access to the QSPI0
  [14] CRYPTOACNR — Allow/Disallow CRYPTO Read access to the QSPI0
  [13] SDMAIACNW — Allow/Disallow SDMA Instruction Write access to the QSPI0
  [12] SDMAIACNR — Allow/Disallow SDMA Instruction Read access to the QSPI0
  [11] SDMADACNW — Allow/Disallow SDMA Data Write access to the QSPI0
  [10] SDMADACNR — Allow/Disallow SDMA Data Read access to the QSPI0
  [9] SYS1ACNW — Allow/Disallow SYS1 Write access to the QSPI0
  [8] SYS1ACNR — Allow/Disallow SYS1 Read access to the QSPI0
  [7] SYS0ACNW — Allow/Disallow SYS0 Write access to the QSPI0
  [6] SYS0ACNR — Allow/Disallow SYS0 Read access to the QSPI0
  [5] USBACNW — Allow/Disallow USB Write access to the QSPI0
  [4] USBACNR — Allow/Disallow USB Read access to the QSPI0
  [3] DMA1ACNW — Allow/Disallow DMA1 Write access to the QSPI0
  [2] DMA1ACNR — Allow/Disallow DMA1 Read access to the QSPI0
  [1] DMA0ACNW — Allow/Disallow DMA0 Write access to the QSPI0
  [0] DMA0ACNR — Allow/Disallow DMA0 Read access to the QSPI0
{0xF00+0x10*i} SRAM{i} (reset mask 0xFFFFFE00) (i=0..6) — SRAM{i} Protection Register
  [all] fields
    1=dis (Disallow); 0=allow
  [17] SDIOACNW — Allow/Disallow SDIO Write access to the SRAM{i}
  [16] SDIOACNR — Allow/Disallow SDIO Read access to the SRAM{i}
  [15] CRYPTOACNW — Allow/Disallow CRYPTO Write access to the SRAM{i}
  [14] CRYPTOACNR — Allow/Disallow CRYPTO Read access to the SRAM{i}
  [13] SDMAIACNW — Allow/Disallow SDMA Instruction Write access to the SRAM{i}
  [12] SDMAIACNR — Allow/Disallow SDMA Instruction Read access to the SRAM{i}
  [11] SDMADACNW — Allow/Disallow SDMA Data Write access to the SRAM{i}
  [10] SDMADACNR — Allow/Disallow SDMA Data Read access to the SRAM{i}
  [9] SYS1ACNW — Allow/Disallow SYS1 Write access to the SRAM{i}
  [8] SYS1ACNR — Allow/Disallow SYS1 Read access to the SRAM{i}
  [7] SYS0ACNW — Allow/Disallow SYS0 Write access to the SRAM{i}
  [6] SYS0ACNR — Allow/Disallow SYS0 Read access to the SRAM{i}
  [5] USBACNW — Allow/Disallow USB Write access to the SRAM{i}
  [4] USBACNR — Allow/Disallow USB Read access to the SRAM{i}
  [3] DMA1ACNW — Allow/Disallow DMA1 Write access to the SRAM{i}
  [2] DMA1ACNR — Allow/Disallow DMA1 Read access to the SRAM{i}
  [1] DMA0ACNW — Allow/Disallow DMA0 Write access to the SRAM{i}
  [0] DMA0ACNR — Allow/Disallow DMA0 Read access to the SRAM{i}
